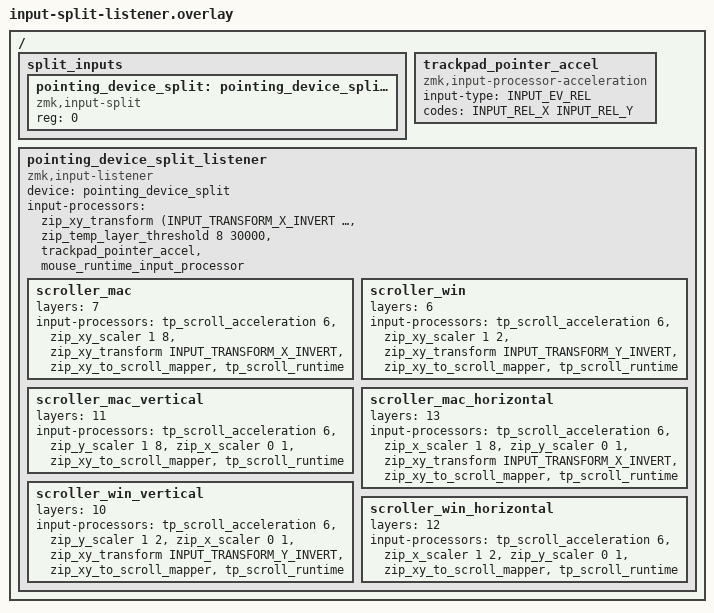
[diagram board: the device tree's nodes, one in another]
/{
    split_inputs {
        #address-cells = <1>;
        #size-cells = <0>;

        pointing_device_split: pointing_device_split@0 {
            compatible = "zmk,input-split";
            reg = <0>;
        };
    };

    trackpad_pointer_accel: trackpad_pointer_accel {
        compatible = "zmk,input-processor-acceleration";
        #input-processor-cells = <0>;
        input-type = <INPUT_EV_REL>;
        codes = <INPUT_REL_X INPUT_REL_Y>;
    };

    pointing_device_split_listener: pointing_device_split_listener {
        compatible = "zmk,input-listener";
        device = <&pointing_device_split>;
        status = "okay";
        /* レイヤー番号は config/keymap.keymap と共通。AML: 8 */
        input-processors =
            <&zip_xy_transform (INPUT_TRANSFORM_X_INVERT | INPUT_TRANSFORM_Y_INVERT)>,
            <&zip_temp_layer_threshold 8 30000>,
            <&trackpad_pointer_accel>,
            <&mouse_runtime_input_processor>;

        // 自由スクロール（Mac）

        scroller_mac {
            layers = <7>;
            input-processors =
                <&tp_scroll_acceleration 6>,
                <&zip_xy_scaler 1 8>,
                <&zip_xy_transform INPUT_TRANSFORM_X_INVERT>,
                <&zip_xy_to_scroll_mapper>,
                <&tp_scroll_runtime>;
        };

        // 自由スクロール（Windows）

        scroller_win {
            layers = <6>;
            input-processors =
                <&tp_scroll_acceleration 6>,
                <&zip_xy_scaler 1 2>,
                <&zip_xy_transform INPUT_TRANSFORM_Y_INVERT>,
                <&zip_xy_to_scroll_mapper>,
                <&tp_scroll_runtime>;
        };

        // 縦スクロール（Mac）

        scroller_mac_vertical {
            layers = <11>;
            input-processors =
                <&tp_scroll_acceleration 6>,
                <&zip_y_scaler 1 8>,
                <&zip_x_scaler 0 1>,
                <&zip_xy_to_scroll_mapper>,
                <&tp_scroll_runtime>;
        };

        // 横スクロール（Mac）

        scroller_mac_horizontal {
            layers = <13>;
            input-processors =
                <&tp_scroll_acceleration 6>,
                <&zip_x_scaler 1 8>,
                <&zip_y_scaler 0 1>,
                <&zip_xy_transform INPUT_TRANSFORM_X_INVERT>,
                <&zip_xy_to_scroll_mapper>,
                <&tp_scroll_runtime>;
        };

        // 縦スクロール（Windows）

        scroller_win_vertical {
            layers = <10>;
            input-processors =
                <&tp_scroll_acceleration 6>,
                <&zip_y_scaler 1 2>,
                <&zip_x_scaler 0 1>,
                <&zip_xy_transform INPUT_TRANSFORM_Y_INVERT>,
                <&zip_xy_to_scroll_mapper>,
                <&tp_scroll_runtime>;
        };

        // 横スクロール（Windows）

        scroller_win_horizontal {
            layers = <12>;
            input-processors =
                <&tp_scroll_acceleration 6>,
                <&zip_x_scaler 1 2>,
                <&zip_y_scaler 0 1>,
                <&zip_xy_to_scroll_mapper>,
                <&tp_scroll_runtime>;
        };
    };
};
